# RE01_256KB register map
Vendor: Renesas Electronics Corporation; Series: RE01; File version: 1.00.01
CPU: CM0PLUS r0p1, little endian, MPU, no FPU, VTOR, 2 interrupt priority bits, 32 interrupts
Registers are 8-bit, read-write, reset 0x0 unless marked. A register's access mark holds for its fields unless they carry their own. Offsets are from the block's base; [hi:lo] are bit positions; {n}, {i} and the like mark numbered series; 'fields as' and 'values as' point back to an identical list.

## RTC — Realtime Clock
Base 0x40044000
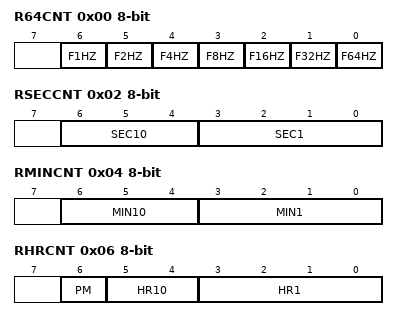
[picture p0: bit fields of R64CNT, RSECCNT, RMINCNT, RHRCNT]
0x00 R64CNT ro — 64-Hz Counter
  [6] F1HZ — 1-Hz Flag
  [5] F2HZ — 2-Hz Flag
  [4] F4HZ — 4-Hz Flag
  [3] F8HZ — 8-Hz Flag
  [2] F16HZ — 16-Hz Flag
  [1] F32HZ — 32-Hz Flag
  [0] F64HZ — 64-Hz Flag
{0x2+2i} BCNT{i} (i=0..3) — Binary Counter {i}
  [7:0] BCNT — Binary Counter
0x02 RSECCNT — Second Counter (in Calendar Count Mode)
  [6:4] SEC10 — 10-Second Count
  [3:0] SEC1 — 1-Second Count
0x04 RMINCNT — Minute Counter (in Calendar Count Mode)
  [6:4] MIN10 — 10-Minute Count
  [3:0] MIN1 — 1-Minute Count
0x06 RHRCNT — Hour Counter (in Calendar Count Mode)
  [6] PM — AM/PM select for time counter setting.
    0=AM; 1=PM
  [5:4] HR10 — 10-Hour Count
  [3:0] HR1 — 1-Hour Count
0x08 RWKCNT — Day-of-Week Counter (in Calendar Count Mode)
  [2:0] DAYW — Day-of-Week Counting
    0=Sunday; 1=Monday; 2=Tuesday; 3=Wednesday; 4=Thursday; 5=Friday; 6=Saturday; 7=Setting prohibited
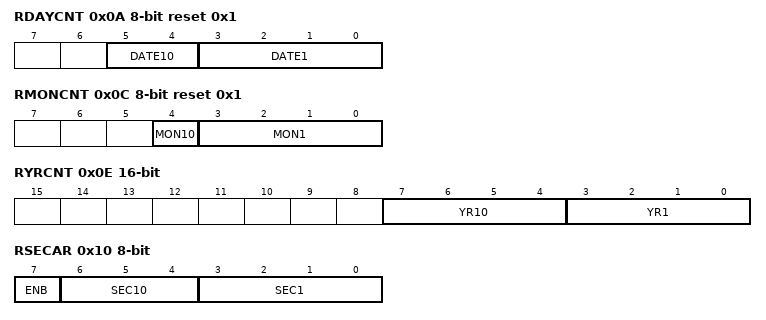
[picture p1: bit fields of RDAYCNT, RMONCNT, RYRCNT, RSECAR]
0x0A RDAYCNT reset 0x1 — Day Counter
  [5:4] DATE10 — 10-Day Count
  [3:0] DATE1 — 1-Day Count
0x0C RMONCNT reset 0x1 — Month Counter
  [4] MON10 — 10-Month Count
  [3:0] MON1 — 1-Month Count
0x0E RYRCNT 16-bit — Year Counter
  [7:4] YR10 — 10-Year Count
  [3:0] YR1 — 1-Year Count
{0x10+2i} BCNT{i}AR (i=0..3) — Binary Counter {i} Alarm Register
  [7:0] BCNTAR — Alarm register associated with the 32-bit binary counter
0x10 RSECAR — Second Alarm Register (in Calendar Count Mode)
  [7] ENB
    0=Do not compare register value with RSECCNT counter value; 1=Compare register value with RSECCNT counter value
  [6:4] SEC10 — 10 Seconds
  [3:0] SEC1 — 1 Second
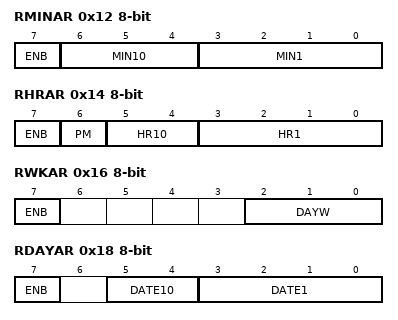
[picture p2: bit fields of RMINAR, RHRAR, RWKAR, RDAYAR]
0x12 RMINAR — Minute Alarm Register (in Calendar Count Mode)
  [7] ENB
    0=Do not compare register value with RMINCNT counter value; 1=Compare register value with RMINCNT counter value
  [6:4] MIN10 — 10 Minutes
  [3:0] MIN1 — 1 Minute
0x14 RHRAR — Hour Alarm Register (in Calendar Count Mode)
  [7] ENB
    0=Do not compare register value with RHRCNT counter value; 1=Compare register value with RHRCNT counter value
  [6] PM — AM/PM select for alarm setting.
    0=AM; 1=PM
  [5:4] HR10 — 10 Hours
  [3:0] HR1 — 1 Hour
0x16 RWKAR — Day-of-Week Alarm Register (in Calendar Count Mode)
  [7] ENB
    0=Do not compare register value with RWKCNT counter value; 1=Compare register value with RWKCNT counter value
  [2:0] DAYW — Day-of-Week Setting
    values as RWKCNT.DAYW
{0x18+2i} BCNT{i}AER (i=0..1) — Binary Counter {i} Alarm Enable Register
  [7:0] ENB — Setting the alarm enable associated with the 32-bit binary counter
0x18 RDAYAR — Date Alarm Register (in Calendar Count Mode)
  [7] ENB
    0=Do not compare register value with RDAYCNT counter value; 1=Compare register value with RDAYCNT counter value
  [5:4] DATE10 — 10 Days
  [3:0] DATE1 — 1 Day
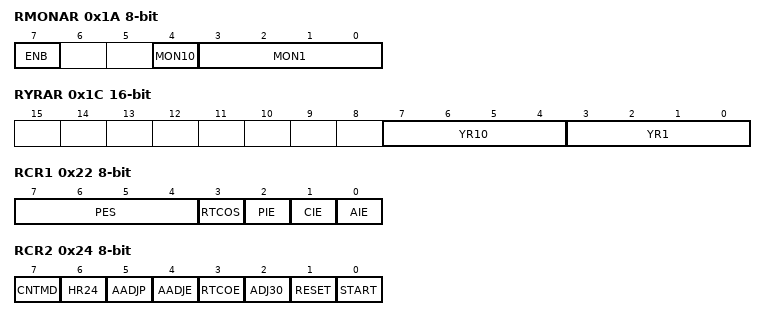
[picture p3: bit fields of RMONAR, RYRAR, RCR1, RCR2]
0x1A RMONAR — Month Alarm Register (in Calendar Count Mode)
  [7] ENB
    0=Do not compare register value with RMONCNT counter value; 1=Compare register value with RMONCNT counter value
  [4] MON10 — 10 Months
  [3:0] MON1 — 1 Month
0x1C BCNT2AER 16-bit — Binary Counter 2 Alarm Enable Register
  fields as BCNT0AER
0x1C RYRAR 16-bit (alternate view of BCNT2AER) — Year Alarm Register (in Calendar Count Mode)
  [7:4] YR10 — 10 Years
  [3:0] YR1 — 1 Year
0x1E BCNT3AER — Binary Counter 3 Alarm Enable Register
  fields as BCNT0AER
0x1E RYRAREN (alternate view of BCNT3AER) — Year Alarm Enable Register (in Calendar Count Mode)
  [7] ENB
    0=Do not compare register value with the RYRCNT counter value; 1=Compare register value with the RYRCNT counter value
0x22 RCR1 — RTC Control Register 1
  [7:4] PES — Periodic Interrupt Select
    6=Generate periodic interrupt every 1/256 second; 7=Generate periodic interrupt every 1/128 second; 8=Generate periodic interrupt every 1/64 second; 9=Generate periodic interrupt every 1/32 second; 10=Generate periodic interrupt every 1/16 second; 11=Generate periodic interrupt every 1/8 second; 12=Generate periodic interrupt every 1/4 second; 13=Generate periodic interrupt every 1/2 second; 14=Generate periodic interrupt every 1 second; 15=Generate periodic interrupt every 2 seconds; other=Others (Do not generate periodic interrupts)
  [3] RTCOS — RTCOUT Output Select
    0=Outputs 1 Hz on RTCOUT; 1=Outputs 64 Hz RTCOUT
  [2] PIE — Periodic Interrupt Enable
    0=Disable periodic interrupt requests; 1=Enable periodic interrupt requests
  [1] CIE — Carry Interrupt Enable
    0=Disable carry interrupt requests; 1=Enable carry interrupt requests
  [0] AIE — Alarm Interrupt Enable
    0=Disable alarm interrupt requests; 1=Enable alarm interrupt requests
0x24 RCR2 — RTC Control Register 2 (in Calendar Count Mode)
  [7] CNTMD — Count Mode Select
    0=Calendar count mode; 1=Binary count mode or 32-kHz count mode
  [6] HR24 — Hours Mode
    0=Operate RTC in 12-hour mode; 1=Operate RTC in 24-hour mode
  [5] AADJP — Automatic Adjustment Period Select
    0=The RADJ.ADJ[5:0] setting from the count value of the prescaler every minute; 1=The RADJ.ADJ[5:0] setting value is adjusted from the coun tvalue of the prescaler every 10 seconds
  [4] AADJE — Automatic Adjustment Enable
    0=Disable automatic adjustment; 1=Enable automatic adjustment
  [3] RTCOE — RTCOUT Output Enable
    0=Disable RTCOUT output; 1=Enable RTCOUT output
  [2] ADJ30 — 30-Second Adjustment
    0=In writing: Invalid (writing 0 has no effect). In reading: Normal time operation in progress, or 30-second adjustment has completed.; 1=In writing: Execute 30-second adjustment. In reading: 30-second adjustment in progress.
  [1] RESET — RTC Software Reset
    0=In writing: Invalid (writing 0 has no effect). In reading: Normal time operation in progress, or an RTC software reset has completed.; 1=In writing: Initialize the prescaler and target registers for RTC software reset. In reading: RTC software reset in progress.
  [0] START
    0=Stop prescaler and time counter; 1=Operate prescaler and time counter normally
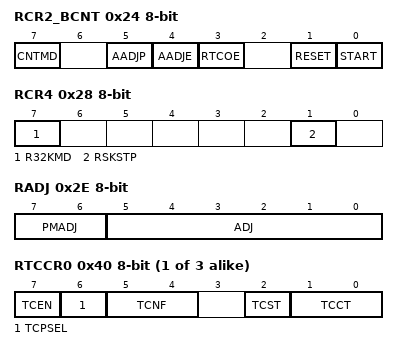
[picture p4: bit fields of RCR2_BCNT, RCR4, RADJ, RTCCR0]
0x24 RCR2_BCNT (alternate view of RCR2) — RTC Control Register 2 (in Binary Count Mode and 32-kHz Count Mode)
  [7] CNTMD — Count Mode Select
    values as RCR2.CNTMD
  [5] AADJP — Automatic Adjustment Period Select
    0=Add or subtract RADJ.ADJ [5:0] bits from prescaler count value every 32 seconds; 1=Add or subtract RADJ.ADJ [5:0] bits from prescaler countvalue every 8 seconds
  [4] AADJE — Automatic Adjustment Enable
    values as RCR2.AADJE
  [3] RTCOE — RTCOUT Output Enable
    0=Disable RTCOUT output; 1=Enable RTCOUT output
  [1] RESET — RTC Software Reset
    values as RCR2.RESET
  [0] START
    0=Stop the 32-bit binary counter, 64-Hz counter, and prescaler; 1=Operate the 32-bit binary counter, 64-Hz counter, and prescaler normally
0x26 RCPE — RTC Time Capture Enable Register
  [0] RTCEN — Time Capture Event Input Enable
    0=Disable the RTCICn pin; 1=Enable the RTCICn pin
0x28 RCR4 — RTC Control Register 4
  [7] R32KMD — 32-kHz Count Mode Enable
    0=Disable 32-kHz count mode; 1=Enable 32-kHz count mode
  [1] RSKSTP — SOSC clock supply setting
    0=Enable SOSC clock supply to RTC; 1=Enable SOSC clock supply to RTC
0x2E RADJ — Time Error Adjustment Register
  [7:6] PMADJ — Plus-Minus
    0=Do not perform adjustment; 1=Adjustment is performed by the addition to the prescaler; 2=Adjustment is performed by the subtraction from the prescaler; 3=Setting prohibited
  [5:0] ADJ — Adjustment Value
{0x40+2i} RTCCR{i} (i=0..2) — Time Capture Control Register {i}
  [7] TCEN — Time Capture Event Input Pin Enable
    0=Disable the RTCICn pin as the time capture event input pin; 1=Enable the RTCICn pin as the time capture event input pin
  [6] TCPSEL — RTCICn input pin select
    0=RTCICn_A; 1=RTCICn_B
  [5:4] TCNF — Time Capture Noise Filter Control
    0=Turn noise filter off; 1=Setting prohibited; 2=Turn noise filter on (count source); 3=Turn noise filter on (count source by divided by 32)
  [2] TCST — Time Capture Status
    0=No event detected; 1=Event detected
  [1:0] TCCT — Time Capture Control
    0=Do not detect events; 1=Detect rising edge; 2=Detect falling edge; 3=Detect both edges
{0x52+0x10*i} BCNT0CP{i} (i=0..2) ro — BCNT0 Capture Register {i}
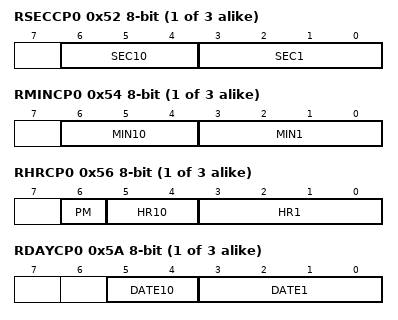
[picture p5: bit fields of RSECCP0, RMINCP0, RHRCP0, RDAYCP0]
{0x52+0x10*i} RSECCP{i} (i=0..2) ro (alternate view of BCNT0CP{i}) — Second Capture Register {i}
  [6:4] SEC10 — 10-Second Capture
  [3:0] SEC1 — 1-Second Capture
{0x54+0x10*i} BCNT1CP{i} (i=0..2) ro — BCNT1 Capture Register {i}
{0x54+0x10*i} RMINCP{i} (i=0..2) ro (alternate view of BCNT1CP{i}) — Minute Capture Register {i}
  [6:4] MIN10 — 10-Minute Capture
  [3:0] MIN1 — 1-Minute Capture
{0x56+0x10*i} BCNT2CP{i} (i=0..2) ro — BCNT2 Capture Register {i}
{0x56+0x10*i} RHRCP{i} (i=0..2) ro (alternate view of BCNT2CP{i}) — Hour Capture Register {i}
  [6] PM
    0=AM; 1=PM
  [5:4] HR10 — 10-Hour Capture
  [3:0] HR1 — 1-Hour Capture
{0x5A+0x10*i} BCNT3CP{i} (i=0..2) ro — BCNT3 Capture Register {i}
{0x5A+0x10*i} RDAYCP{i} (i=0..2) ro (alternate view of BCNT3CP{i}) — Date Capture Register {i}
  [5:4] DATE10 — 10-Day Capture
  [3:0] DATE1 — 1-Day Capture
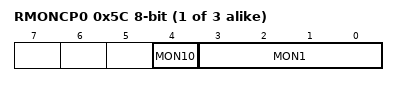
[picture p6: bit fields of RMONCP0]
{0x5C+0x10*i} RMONCP{i} (i=0..2) ro — Month Capture Register {i}
  [4] MON10 — 10-Month Capture
  [3:0] MON1 — 1-Month Capture
